# ESP32-S2 register map
Vendor: ESPRESSIF SYSTEMS (SHANGHAI) CO., LTD.; Series: ESP32 S-Series; File version: 20
CPU: Xtensa LX7 r0p0, little endian, no MPU, no FPU, 0 interrupt priority bits
Address unit: 32 bits
Registers are 32-bit, read-write, reset 0x0 unless marked. A register's access mark holds for its fields unless they carry their own. Offsets are from the block's base; [hi:lo] are bit positions; {n}, {i} and the like mark numbered series.

## I2C0 — I2C (Inter-Integrated Circuit) Controller 0
Base 0x3F413000
Same registers: I2C1 0x3F427000
0x00 SCL_LOW_PERIOD — Configures the low level width of the SCL clock
  [13:0] SCL_LOW_PERIOD — This register is used to configure for how long SCL remains low in master mode, in I2C module clock cycles.
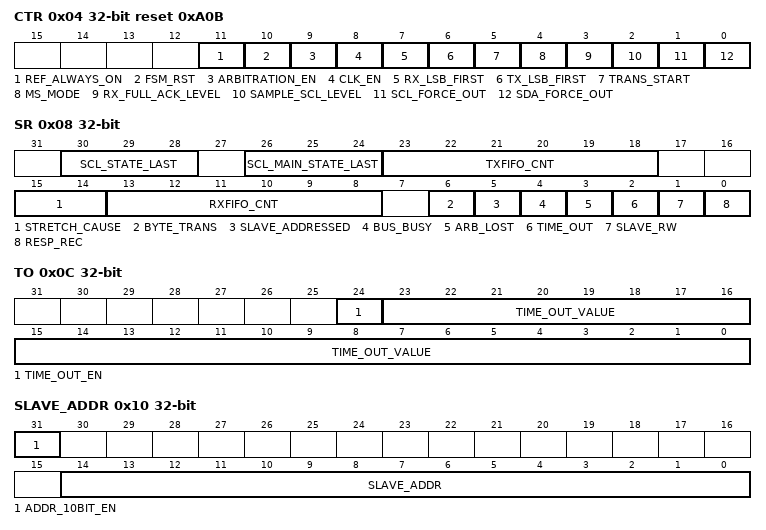
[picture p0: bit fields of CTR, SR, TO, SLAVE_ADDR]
0x04 CTR reset 0xA0B — Transmission setting
  [11] REF_ALWAYS_ON — This register is used to control the REF_TICK.
  [10] FSM_RST — This register is used to reset the SCL_FSM.
  [9] ARBITRATION_EN — This is the enable bit for I2C bus arbitration function.
  [8] CLK_EN — Reserved.
  [7] RX_LSB_FIRST — This bit is used to control the storage mode for received data. 1: receive data from the least significant bit. 0: receive data from the most significant bit.
  [6] TX_LSB_FIRST — This bit is used to control the sending mode for data needing to be sent. 1: send data from the least significant bit. 0: send data from the most significant bit.
  [5] TRANS_START — Set this bit to start sending the data in TX FIFO.
  [4] MS_MODE — Set this bit to configure the module as an I2C Master. Clear this bit to configure the module as an I2C Slave.
  [3] RX_FULL_ACK_LEVEL — This register is used to configure the ACK value that need to sent by master when the rx_fifo_cnt has reached the threshold.
  [2] SAMPLE_SCL_LEVEL — This register is used to select the sample mode. 1: sample SDA data on the SCL low level. 0: sample SDA data on the SCL high level.
  [1] SCL_FORCE_OUT — 0: direct output. 1: open drain output.
  [0] SDA_FORCE_OUT — 0: direct output. 1: open drain output.
0x08 SR ro — Describe I2C work status
  [30:28] SCL_STATE_LAST — This field indicates the states of the state machine used to produce SCL. 0: Idle. 1: Start. 2: Negative edge. 3: Low. 4: Positive edge. 5: High. 6: Stop
  [26:24] SCL_MAIN_STATE_LAST — This field indicates the states of the I2C module state machine. 0: Idle. 1: Address shift. 2: ACK address. 3: RX data. 4: TX data. 5: Send ACK. 6: Wait ACK
  [23:18] TXFIFO_CNT — This field stores the amount of received data in RAM.
  [15:14] STRETCH_CAUSE — The cause of stretching SCL low in slave mode. 0: stretching SCL low at the beginning of I2C read data state. 1: stretching SCL low when I2C TX FIFO is empty in slave mode. 2: stretching SCL low when I2C RX FIFO is full in slave mode.
  [13:8] RXFIFO_CNT — This field represents the amount of data needed to be sent.
  [6] BYTE_TRANS — This field changes to 1 when one byte is transferred.
  [5] SLAVE_ADDRESSED — When configured as an I2C Slave, and the address sent by the master is equal to the address of the slave, then this bit will be of high level.
  [4] BUS_BUSY — 1: the I2C bus is busy transferring data. 0: the I2C bus is in idle state.
  [3] ARB_LOST — When the I2C controller loses control of SCL line, this register changes to 1.
  [2] TIME_OUT — When the I2C controller takes more than I2C_TIME_OUT clocks to receive a data bit, this field changes to 1.
  [1] SLAVE_RW — When in slave mode, 1: master reads from slave. 0: master writes to slave.
  [0] RESP_REC — The received ACK value in master mode or slave mode. 0: ACK. 1: NACK.
0x0C TO — Setting time out control for receiving data
  [24] TIME_OUT_EN — This is the enable bit for time out control.
  [23:0] TIME_OUT_VALUE — This register is used to configure the timeout for receiving a data bit in APB clock cycles.
0x10 SLAVE_ADDR — Local slave address setting
  [31] ADDR_10BIT_EN — This field is used to enable the slave 10-bit addressing mode in master mode.
  [14:0] SLAVE_ADDR — When configured as an I2C Slave, this field is used to configure the slave address.
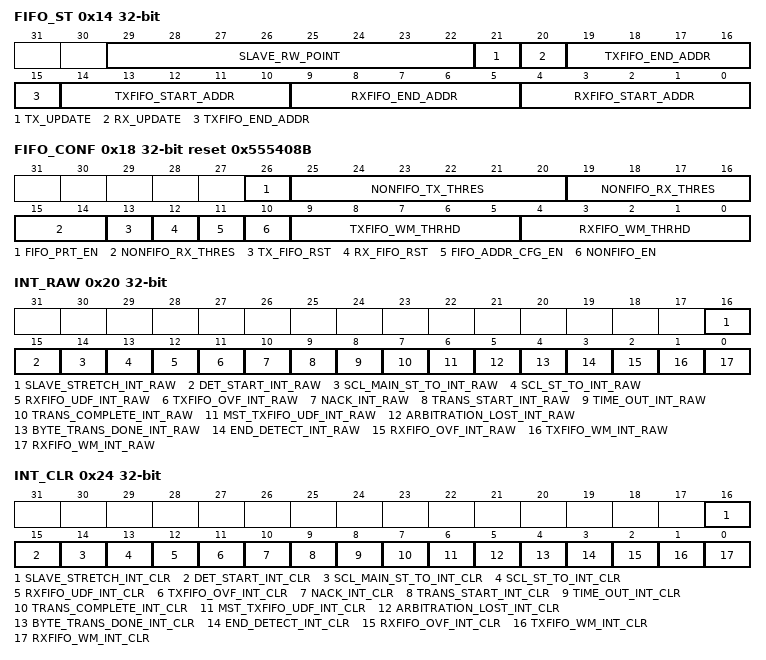
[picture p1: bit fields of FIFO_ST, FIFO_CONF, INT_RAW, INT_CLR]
0x14 FIFO_ST access per field — FIFO status register
  [29:22] SLAVE_RW_POINT ro — The received data in I2C slave mode.
  [21] TX_UPDATE wo — Write 0 or 1 to I2C_TX_UPDATE to update the value of I2C_TXFIFO_END_ADDR and I2C_TXFIFO_START_ADDR.
  [20] RX_UPDATE wo — Write 0 or 1 to I2C_RX_UPDATE to update the value of I2C_RXFIFO_END_ADDR and I2C_RXFIFO_START_ADDR.
  [19:15] TXFIFO_END_ADDR ro — This is the offset address of the last sent data, as described in I2C_NONFIFO_TX_THRES. The value refreshes when an I2C_TXFIFO_OVF_INT or I2C_TRANS_COMPLETE_INT interrupt is generated.
  [14:10] TXFIFO_START_ADDR ro — This is the offset address of the first sent data, as described in I2C_NONFIFO_TX_THRES.
  [9:5] RXFIFO_END_ADDR ro — This is the offset address of the last received data, as described in I2C_NONFIFO_RX_THRES. This value refreshes when an I2C_RXFIFO_UDF_INT or I2C_TRANS_COMPLETE_INT interrupt is generated.
  [4:0] RXFIFO_START_ADDR ro — This is the offset address of the last received data, as described in I2C_NONFIFO_RX_THRES.
0x18 FIFO_CONF reset 0x555408B — FIFO configuration register
  [26] FIFO_PRT_EN — The control enable bit of FIFO pointer in non-FIFO mode. This bit controls the valid bits and the interrupts of TX/RX FIFO overflow, underflow, full and empty.
  [25:20] NONFIFO_TX_THRES — When I2C sends more than I2C_NONFIFO_TX_THRES bytes of data, it will generate an I2C_TXFIFO_OVF_INT interrupt and update the current offset address of the sent data.
  [19:14] NONFIFO_RX_THRES — When I2C receives more than I2C_NONFIFO_RX_THRES bytes of data, it will generate an I2C_RXFIFO_UDF_INT interrupt and update the current offset address of the received data.
  [13] TX_FIFO_RST — Set this bit to reset TX FIFO.
  [12] RX_FIFO_RST — Set this bit to reset RX FIFO.
  [11] FIFO_ADDR_CFG_EN — When this bit is set to 1, the byte received after the I2C address byte represents the offset address in the I2C Slave RAM.
  [10] NONFIFO_EN — Set this bit to enable APB non-FIFO mode.
  [9:5] TXFIFO_WM_THRHD — The water mark threshold of TX FIFO in non-FIFO mode. When I2C_FIFO_PRT_EN is 1 and TX FIFO counter is smaller than I2C_TXFIFO_WM_THRHD[4:0], I2C_TXFIFO_WM_INT_RAW bit will be valid.
  [4:0] RXFIFO_WM_THRHD — The water mark threshold of RX FIFO in non-FIFO mode. When I2C_FIFO_PRT_EN is 1 and RX FIFO counter is bigger than I2C_RXFIFO_WM_THRHD[4:0], I2C_RXFIFO_WM_INT_RAW bit will be valid.
0x1C DATA ro — RX FIFO read data
  [7:0] FIFO_RDATA — The value of RX FIFO read data.
0x20 INT_RAW ro — Raw interrupt status
  [16] SLAVE_STRETCH_INT_RAW — The raw interrupt bit for I2C_SLAVE_STRETCH_INT interrupt.
  [15] DET_START_INT_RAW — The raw interrupt bit for I2C_DET_START_INT interrupt.
  [14] SCL_MAIN_ST_TO_INT_RAW — The raw interrupt bit for I2C_SCL_MAIN_ST_TO_INT interrupt.
  [13] SCL_ST_TO_INT_RAW — The raw interrupt bit for I2C_SCL_ST_TO_INT interrupt.
  [12] RXFIFO_UDF_INT_RAW — The raw interrupt bit for I2C_RXFIFO_UDF_INT interrupt.
  [11] TXFIFO_OVF_INT_RAW — The raw interrupt bit for I2C_TXFIFO_OVF_INT interrupt.
  [10] NACK_INT_RAW — The raw interrupt bit for I2C_SLAVE_STRETCH_INT interrupt.
  [9] TRANS_START_INT_RAW — The raw interrupt bit for the I2C_TRANS_START_INT interrupt.
  [8] TIME_OUT_INT_RAW — The raw interrupt bit for the I2C_TIME_OUT_INT interrupt.
  [7] TRANS_COMPLETE_INT_RAW — The raw interrupt bit for the I2C_TRANS_COMPLETE_INT interrupt.
  [6] MST_TXFIFO_UDF_INT_RAW — The raw interrupt bit for I2C_TRANS_COMPLETE_INT interrupt.
  [5] ARBITRATION_LOST_INT_RAW — The raw interrupt bit for the I2C_ARBITRATION_LOST_INT interrupt.
  [4] BYTE_TRANS_DONE_INT_RAW — The raw interrupt bit for the I2C_END_DETECT_INT interrupt.
  [3] END_DETECT_INT_RAW — The raw interrupt bit for the I2C_END_DETECT_INT interrupt.
  [2] RXFIFO_OVF_INT_RAW — The raw interrupt bit for I2C_RXFIFO_OVF_INT interrupt.
  [1] TXFIFO_WM_INT_RAW — The raw interrupt bit for I2C_TXFIFO_WM_INT interrupt.
  [0] RXFIFO_WM_INT_RAW — The raw interrupt bit for I2C_RXFIFO_WM_INT interrupt.
0x24 INT_CLR wo — Interrupt clear bits
  [16] SLAVE_STRETCH_INT_CLR — Set this bit to clear I2C_SLAVE_STRETCH_INT interrupt.
  [15] DET_START_INT_CLR — Set this bit to clear I2C_DET_START_INT interrupt.
  [14] SCL_MAIN_ST_TO_INT_CLR — Set this bit to clear I2C_SCL_MAIN_ST_TO_INT interrupt.
  [13] SCL_ST_TO_INT_CLR — Set this bit to clear I2C_SCL_ST_TO_INT interrupt.
  [12] RXFIFO_UDF_INT_CLR — Set this bit to clear I2C_RXFIFO_UDF_INT interrupt.
  [11] TXFIFO_OVF_INT_CLR — Set this bit to clear I2C_TXFIFO_OVF_INT interrupt.
  [10] NACK_INT_CLR — Set this bit to clear I2C_SLAVE_STRETCH_INT interrupt.
  [9] TRANS_START_INT_CLR — Set this bit to clear the I2C_TRANS_START_INT interrupt.
  [8] TIME_OUT_INT_CLR — Set this bit to clear the I2C_TIME_OUT_INT interrupt.
  [7] TRANS_COMPLETE_INT_CLR — Set this bit to clear the I2C_TRANS_COMPLETE_INT interrupt.
  [6] MST_TXFIFO_UDF_INT_CLR — Set this bit to clear I2C_TRANS_COMPLETE_INT interrupt.
  [5] ARBITRATION_LOST_INT_CLR — Set this bit to clear the I2C_ARBITRATION_LOST_INT interrupt.
  [4] BYTE_TRANS_DONE_INT_CLR — Set this bit to clear the I2C_END_DETECT_INT interrupt.
  [3] END_DETECT_INT_CLR — Set this bit to clear the I2C_END_DETECT_INT interrupt.
  [2] RXFIFO_OVF_INT_CLR — Set this bit to clear I2C_RXFIFO_OVF_INT interrupt.
  [1] TXFIFO_WM_INT_CLR — Set this bit to clear I2C_TXFIFO_WM_INT interrupt.
  [0] RXFIFO_WM_INT_CLR — Set this bit to clear I2C_RXFIFO_WM_INT interrupt.
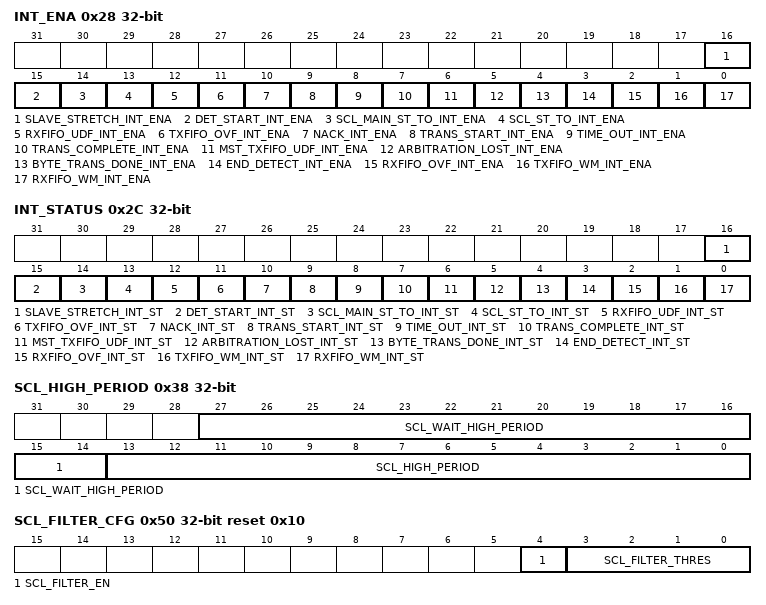
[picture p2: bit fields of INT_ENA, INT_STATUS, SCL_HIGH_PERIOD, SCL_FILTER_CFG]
0x28 INT_ENA — Interrupt enable bits
  [16] SLAVE_STRETCH_INT_ENA — The raw interrupt bit for I2C_SLAVE_STRETCH_INT interrupt.
  [15] DET_START_INT_ENA — The raw interrupt bit for I2C_DET_START_INT interrupt.
  [14] SCL_MAIN_ST_TO_INT_ENA — The raw interrupt bit for I2C_SCL_MAIN_ST_TO_INT interrupt.
  [13] SCL_ST_TO_INT_ENA — The raw interrupt bit for I2C_SCL_ST_TO_INT interrupt.
  [12] RXFIFO_UDF_INT_ENA — The raw interrupt bit for I2C_RXFIFO_UDF_INT interrupt.
  [11] TXFIFO_OVF_INT_ENA — The raw interrupt bit for I2C_TXFIFO_OVF_INT interrupt.
  [10] NACK_INT_ENA — The raw interrupt bit for I2C_SLAVE_STRETCH_INT interrupt.
  [9] TRANS_START_INT_ENA — The raw interrupt bit for the I2C_TRANS_START_INT interrupt.
  [8] TIME_OUT_INT_ENA — The raw interrupt bit for the I2C_TIME_OUT_INT interrupt.
  [7] TRANS_COMPLETE_INT_ENA — The raw interrupt bit for the I2C_TRANS_COMPLETE_INT interrupt.
  [6] MST_TXFIFO_UDF_INT_ENA — The raw interrupt bit for I2C_TRANS_COMPLETE_INT interrupt.
  [5] ARBITRATION_LOST_INT_ENA — The raw interrupt bit for the I2C_ARBITRATION_LOST_INT interrupt.
  [4] BYTE_TRANS_DONE_INT_ENA — The raw interrupt bit for the I2C_END_DETECT_INT interrupt.
  [3] END_DETECT_INT_ENA — The raw interrupt bit for the I2C_END_DETECT_INT interrupt.
  [2] RXFIFO_OVF_INT_ENA — The raw interrupt bit for I2C_RXFIFO_OVF_INT interrupt.
  [1] TXFIFO_WM_INT_ENA — The raw interrupt bit for I2C_TXFIFO_WM_INT interrupt.
  [0] RXFIFO_WM_INT_ENA — The raw interrupt bit for I2C_RXFIFO_WM_INT interrupt.
0x2C INT_STATUS ro — Status of captured I2C communication events
  [16] SLAVE_STRETCH_INT_ST — The masked interrupt status bit for I2C_SLAVE_STRETCH_INT interrupt.
  [15] DET_START_INT_ST — The masked interrupt status bit for I2C_DET_START_INT interrupt.
  [14] SCL_MAIN_ST_TO_INT_ST — The masked interrupt status bit for I2C_SCL_MAIN_ST_TO_INT interrupt.
  [13] SCL_ST_TO_INT_ST — The masked interrupt status bit for I2C_SCL_ST_TO_INT interrupt.
  [12] RXFIFO_UDF_INT_ST — The masked interrupt status bit for I2C_RXFIFO_UDF_INT interrupt.
  [11] TXFIFO_OVF_INT_ST — The masked interrupt status bit for I2C_TXFIFO_OVF_INT interrupt.
  [10] NACK_INT_ST — The masked interrupt status bit for I2C_SLAVE_STRETCH_INT interrupt.
  [9] TRANS_START_INT_ST — The masked interrupt status bit for the I2C_TRANS_START_INT interrupt.
  [8] TIME_OUT_INT_ST — The masked interrupt status bit for the I2C_TIME_OUT_INT interrupt.
  [7] TRANS_COMPLETE_INT_ST — The masked interrupt status bit for the I2C_TRANS_COMPLETE_INT interrupt.
  [6] MST_TXFIFO_UDF_INT_ST — The masked interrupt status bit for I2C_TRANS_COMPLETE_INT interrupt.
  [5] ARBITRATION_LOST_INT_ST — The masked interrupt status bit for the I2C_ARBITRATION_LOST_INT interrupt.
  [4] BYTE_TRANS_DONE_INT_ST — The masked interrupt status bit for the I2C_END_DETECT_INT interrupt.
  [3] END_DETECT_INT_ST — The masked interrupt status bit for the I2C_END_DETECT_INT interrupt.
  [2] RXFIFO_OVF_INT_ST — The masked interrupt status bit for I2C_RXFIFO_OVF_INT interrupt.
  [1] TXFIFO_WM_INT_ST — The masked interrupt status bit for I2C_TXFIFO_WM_INT interrupt.
  [0] RXFIFO_WM_INT_ST — The masked interrupt status bit for I2C_RXFIFO_WM_INT interrupt.
0x30 SDA_HOLD — Configures the hold time after a negative SCL edge
  [9:0] TIME — This register is used to configure the interval between changing the SDA output level and the falling edge of SCL, in I2C module clock cycles.
0x34 SDA_SAMPLE — Configures the sample time after a positive SCL edge
  [9:0] TIME — This register is used to configure the interval between the rising edge of SCL and the level sampling time of SDA, in I2C module clock cycles.
0x38 SCL_HIGH_PERIOD — Configures the high level width of the SCL clock
  [27:14] SCL_WAIT_HIGH_PERIOD — This register is used to configure for the SCL_FSM's waiting period for SCL to go high in master mode, in I2C module clock cycles.
  [13:0] SCL_HIGH_PERIOD — This register is used to configure for how long SCL remains high in master mode, in I2C module clock cycles.
0x40 SCL_START_HOLD reset 0x8 — Configures the interval between pulling SDA low and pulling SCL low when the master generates a START condition
  [9:0] TIME — This register is used to configure interval between pulling SDA low and pulling SCL low when the master generates a START condition, in I2C module clock cycles.
0x44 SCL_RSTART_SETUP reset 0x8 — Configures the interval between the positive edge of SCL and the negative edge of SDA
  [9:0] TIME — This register is used to configure the interval between the positive edge of SCL and the negative edge of SDA for a RESTART condition, in I2C module clock cycles.
0x48 SCL_STOP_HOLD — Configures the delay after the SCL clock edge for a stop condition
  [13:0] TIME — This register is used to configure the delay after the STOP condition, in I2C module clock cycles.
0x4C SCL_STOP_SETUP — Configures the delay between the SDA and SCL positive edge for a stop condition
  [9:0] TIME — This register is used to configure the time between the positive edge of SCL and the positive edge of SDA, in I2C module clock cycles.
0x50 SCL_FILTER_CFG reset 0x10 — SCL filter configuration register
  [4] SCL_FILTER_EN — This is the filter enable bit for SCL.
  [3:0] SCL_FILTER_THRES — When a pulse on the SCL input has smaller width than this register value in I2C module clock cycles, the I2C controller will ignore that pulse.
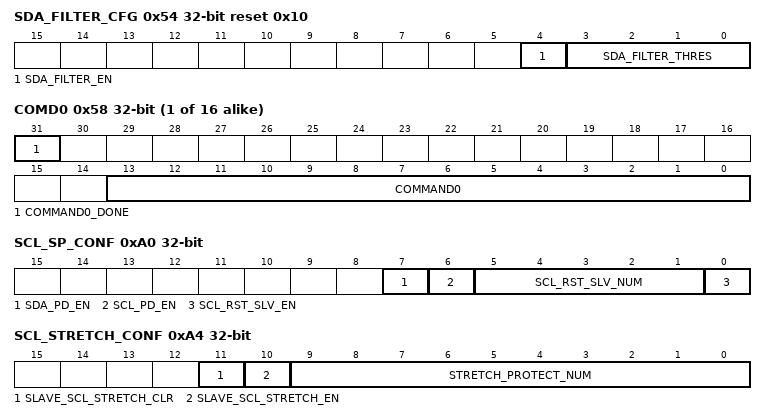
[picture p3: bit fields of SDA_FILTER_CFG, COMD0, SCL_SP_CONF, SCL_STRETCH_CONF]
0x54 SDA_FILTER_CFG reset 0x10 — SDA filter configuration register
  [4] SDA_FILTER_EN — This is the filter enable bit for SDA.
  [3:0] SDA_FILTER_THRES — When a pulse on the SDA input has smaller width than this register value in I2C module clock cycles, the I2C controller will ignore that pulse.
{0x58+4i} COMD{i} (i=0..15) — I2C command register {i}
  [31] COMMAND{i}_DONE — When command {i} is done in I2C Master mode, this bit changes to high level.
  [13:0] COMMAND{i} — This is the content of command {i}. It consists of three parts: op_code is the command, 0: RSTART. 1: WRITE. 2: READ. 3: STOP. 4: END. byte_num represents the number of bytes that need to be sent or received. ack_check_en, ack_exp and ack are used to control the ACK bit. See I2C cmd structure for more information.
0x98 SCL_ST_TIME_OUT reset 0x100 — SCL status time out register
  [23:0] SCL_ST_TO — The threshold value of SCL_FSM state unchanged period.
0x9C SCL_MAIN_ST_TIME_OUT reset 0x100 — SCL main status time out register
  [23:0] SCL_MAIN_ST_TO — The threshold value of SCL_MAIN_FSM state unchanged period.
0xA0 SCL_SP_CONF — Power configuration register
  [7] SDA_PD_EN — The power down enable bit for the I2C output SDA line. 1: Power down. 0: Not power down. Set I2C_SDA_FORCE_OUT and I2C_SDA_PD_EN to 1 to stretch SDA low.
  [6] SCL_PD_EN — The power down enable bit for the I2C output SCL line. 1: Power down. 0: Not power down. Set I2C_SCL_FORCE_OUT and I2C_SCL_PD_EN to 1 to stretch SCL low.
  [5:1] SCL_RST_SLV_NUM — Configure the pulses of SCL generated in I2C master mode. Valid when I2C_SCL_RST_SLV_EN is 1.
  [0] SCL_RST_SLV_EN — When I2C master is IDLE, set this bit to send out SCL pulses. The number of pulses equals to I2C_SCL_RST_SLV_NUM[4:0].
0xA4 SCL_STRETCH_CONF access per field — Set SCL stretch of I2C slave
  [11] SLAVE_SCL_STRETCH_CLR wo — Set this bit to clear the I2C slave SCL stretch function.
  [10] SLAVE_SCL_STRETCH_EN rw — The enable bit for slave SCL stretch function. 1: Enable. 0: Disable. The SCL output line will be stretched low when I2C_SLAVE_SCL_STRETCH_EN is 1 and stretch event happens. The stretch cause can be seen in I2C_STRETCH_CAUSE.
  [9:0] STRETCH_PROTECT_NUM rw — Configure the period of I2C slave stretching SCL line.
0xF8 DATE reset 0x19052000 — Version control register
  [31:0] DATE — This is the the version control register.
